# RZT2L register map
Vendor: Renesas Electronics Corporation; Series: RZT; File version: 1.20.00
CPU: other r0p0, little endian, MPU, no FPU, VTOR, 4 interrupt priority bits, 624 interrupts
Registers are 32-bit, read-write, reset 0x0 unless marked. A register's access mark holds for its fields unless they carry their own. Offsets are from the block's base; [hi:lo] are bit positions; {n}, {i} and the like mark numbered series; 'fields as' and 'values as' point back to an identical list.

## SYSC_S — Register Write Protection for Safety Area
Base 0x81280000
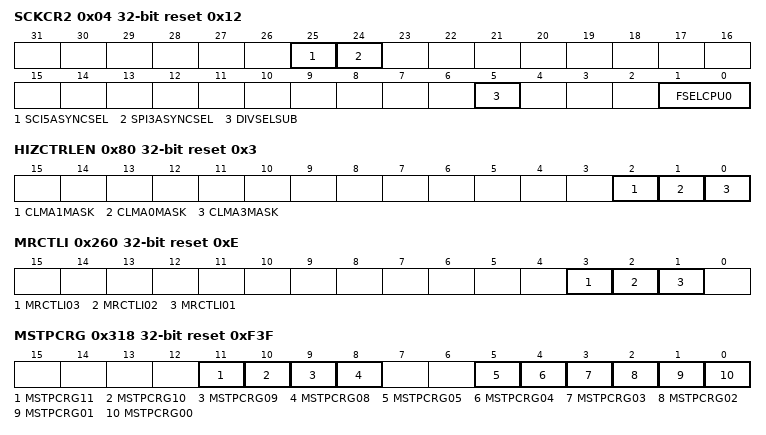
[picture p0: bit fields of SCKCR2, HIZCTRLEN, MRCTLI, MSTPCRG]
0x04 SCKCR2 reset 0x12 — System Clock Control Register 2
  [25] SCI5ASYNCSEL — Select clock frequency when asynchronous serial clock is selected in SCI5
    0=75.0 MHz; 1=96.0 MHz
  [24] SPI3ASYNCSEL — Select clock frequency when asynchronous serial clock is selected in SPI3
    0=75.0 MHz; 1=96.0 MHz
  [5] DIVSELSUB — Select the base clock frequency for peripheral module.
  [1:0] FSELCPU0 — Set the frequency of the clock provided to Coretex-R52 CPU0 in combination with bit 5 (DIVSELSUB). The combination is shown below.
0x20 PLL0MON ro reset 0x1 — PLL0 Monitor Register
  [0] PLL0MON — PLL0 Lock State Monitor
    0=PLL0 is not locked; 1=PLL0 is locked
0x40 PLL1MON ro (reset mask 0xFFFFFFFE) — PLL1 Monitor Register
  [0] PLL1MON — PLL1 Lock State Monitor
    0=PLL1 is not locked; 1=PLL1 is locked
0x50 PLL1EN reset 0x1 — PLL1 Enable Register
  [0] PLL1EN — PLL1 Enable
    0=PLL1 is in standby state; 1=PLL1 is in normal state
0x70 LOCOCR — Low-Speed On-Chip Oscillator Control Register
  [0] LCSTP — LOCO Stop
    0=Stop; 1=Run
0x80 HIZCTRLEN reset 0x3 — High-Impedance Control Enable Register
  [2] CLMA1MASK — CLMA1 error mask to POE3 and POEG
    0=CLMA1 error is not transferred to POE3 and POEG; 1=CLMA1 error is transferred to POE3 and POEG
  [1] CLMA0MASK — CLMA0 error mask to POE3 and POEG
    0=CLMA0 error is not transferred to POE3 and POEG; 1=CLMA0 error is transferred to POE3 and POEG
  [0] CLMA3MASK — CLMA3 error mask to POE3 and POEG
    0=CLMA3 error is not transferred to POE3 and POEG; 1=CLMA3 error is transferred to POE3 and POEG
0x210 SWRSYS wo — System Software Reset Register
  [31:0] SWR — System Software Reset
0x220 SWRCPU0 — CPU0 Software Reset Register
  [31:0] SWR — CPU0 Software Reset
0x260 MRCTLI reset 0xE — Module Reset Control Register I
  [all] fields
    0=Reset released; 1=Reset state
  [3] MRCTLI03
  [2] MRCTLI02
  [1] MRCTLI01
0x314 MSTPCRF — Module Stop Control Register F
  [0] MSTPCRF00 — Trace Clock for Debugging Interface Module Stop
    0=Release from the module-stop state; 1=Transition to the module-stop state is made
0x318 MSTPCRG reset 0xF3F — Module Stop Control Register G
  [all] fields
    values as MSTPCRF.MSTPCRF00
  [11] MSTPCRG11 — CLMA2 Module Stop
  [10] MSTPCRG10 — CLMA1 Module Stop
  [9] MSTPCRG09 — CLMA0 Module Stop
  [8] MSTPCRG08 — CLMA3 Module Stop
  [5] MSTPCRG05 — RTC Module Stop
  [4] MSTPCRG04 — CRC Unit 1 Module Stop
  [3] MSTPCRG03 — GPT Unit 2 Module Stop
  [2] MSTPCRG02 — SPI Unit 3 Module Stop
  [1] MSTPCRG01 — IIC Unit 2 Module Stop
  [0] MSTPCRG00 — SCI Unit 5 Module Stop
0x320 MSTPCRI reset 0x2 — Module Stop Control Register I
  [1] MSTPCRI01 — SHOSTIF Module Stop
    values as MSTPCRF.MSTPCRF00

## CLMA0 — Clock Monitor Circuit 0
Base 0x81280800
Same registers: CLMA1 0x81280820, CLMA2 0x81280840, CLMA3 0x81280860
0x00 CTL0 8-bit — CLMA Control Register 0
  [0] CLME — Clock Monitor m Enable (m = 0 to 3)
    0=Disables CLMAm operation; 1=Enables CLMAm operation
0x08 CMPL 16-bit reset 0x1 — CLMA Compare Register L
  [11:0] CMPL — Clock Monitor m Compare L (m = 0 to 3)
0x0C CMPH 16-bit reset 0x3FF — CLMA Compare Register H
  [11:0] CMPH — Clock Monitor m Compare H (m = 0 to 3)
0x10 PCMD 8-bit wo reset 0xFF — CLMA Command Register
0x14 PROTSR 8-bit ro — CLMA Protection Status Register
  [0] PRERR — CLMAm Error (m = 0 to 3)
    0=No protection error occurred; 1=A protection error occurred

## MPU0 — Master MPU 0
Base 0x81281100
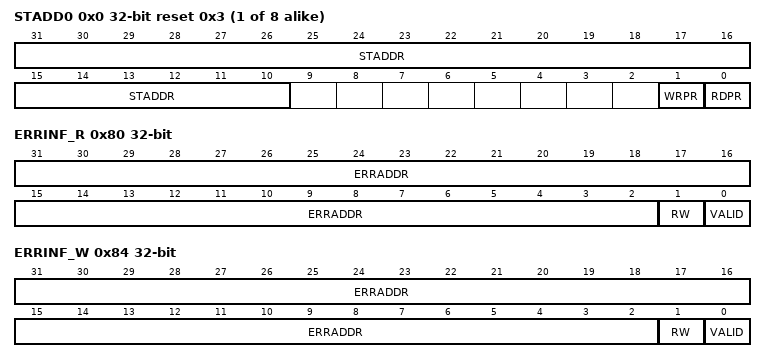
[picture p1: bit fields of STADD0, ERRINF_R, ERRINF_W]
{0x0+0x10*i} STADD{i} (i=0..7) reset 0x3 — Master MPU Safety Region Start Address Register {i}
  [31:10] STADDR — Start address for MPU region
  [1] WRPR — Enable write protection for region m of master MPU
    0=Disable write protection. Write access to the safety region is permitted.; 1=Enable write protection. Write access to the safety region is protected and error is generated.
  [0] RDPR — Enable read protection for region m of master MPU
    0=Disable read protection. Read access to the safety region is permitted.; 1=Enable read protection. Read access to the safety region is protected and error is generated.
{0x4+0x10*i} ENDADD{i} (i=0..7) reset 0xFFFFFC00 — Master MPU Safety Region End Address Register {i}
  [31:10] ENDADDR — End address for MPU region
0x80 ERRINF_R — Master MPU Error Information Register for AXI type
  [31:2] ERRADDR ro — Access error address
  [1] RW ro — Access error type
    0=Read access; 1=Write access
  [0] VALID — Validity of access error information
    0=Error information is invalid; 1=Error information is valid
0x84 ERRINF_W — Master MPU Error Information Register for AXI type
  fields as ERRINF_R

## MPU7 — Master MPU 7
Base 0x81281C00
Registers as MPU0, without ERRINF_R, ERRINF_W; these are added or differ:
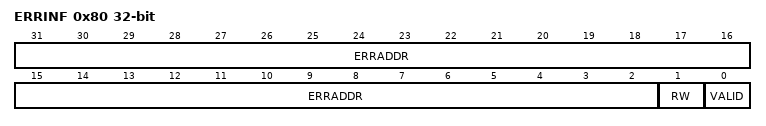
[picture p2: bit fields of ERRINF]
0x80 ERRINF — Master MPU Error Information Register for AHB type
  [31:2] ERRADDR ro — Access Error Address
  [1] RW ro — Access error type
    0=Read access; 1=Write access
  [0] VALID — Validity of Access Error Information
    0=Error information is invalid; 1=Error information is valid
